# PIC32CM2532JH00100 register map
Vendor: Microchip Technology; Series: PIC32CMJH00; File version: 0
CPU: CM0+ r0p0, little endian, MPU, no FPU, VTOR, 2 interrupt priority bits, 32 interrupts
Registers are 32-bit, read-write, reset 0x0 unless marked. A register's access mark holds for its fields unless they carry their own. Offsets are from the block's base; [hi:lo] are bit positions; lines under a group give offsets from that group; {n}, {i} and the like mark numbered series; 'fields as' and 'values as' point back to an identical list.

## SERCOM0 — Serial Communication Interface
Base 0x42000400; register names take the prefix SERCOM_
Same registers: SERCOM1 0x42000800, SERCOM2 0x42000C00, SERCOM3 0x42001000, SERCOM4 0x42001400, SERCOM5 0x42001800, SERCOM6 0x43000000, SERCOM7 0x43000400
0x00 I2CM group — I2C Host Mode
  0x00 CTRLA — I2CM Control A
    [30] LOWTOUTEN — SCL Low Time-Out
    [29:28] INACTOUT — Inactive Time-Out
      0=DIS (Disabled); 1=55US (5-6 SCL cycle time-out (50-60 us)); 2=105US (10-11 SCL cycle time-out (100-110 us)); 3=205US (20-21 SCL cycle time-out (200-210 us))
    [27] SCLSM — SCL Clock Stretch Mode
    [25:24] SPEED — Transfer Speed
      0=SM_MODE (Standard-mode (Sm) and Fast-mode (Fm)); 1=FASTPLUS_MODE (Fast-mode Plus (Fm+))
    [23] SEXTTOEN — Client SCL Low Extend Time-Out
    [22] MEXTTOEN — Host SCL Low Extend Time-Out
    [21:20] SDAHOLD — SDA Hold Time
      0=DIS (SDA hold time is disabled); 1=75NS (SDA hold time is 50-100 ns); 2=450NS (SDA hold time is 300-600 ns); 3=600NS (SDA hold time is 400-800 ns)
    [16] PINOUT — Pin Usage
    [7] RUNSTDBY — Run in Standby
    [4:2] MODE — Operating Mode
      0=USART_EXT (USART with external clock); 1=USART_INT (USART with internal clock); 2=SPI_SLAVE (SPI Client mode); 3=SPI_MASTER (SPI Host mode); 4=I2C_SLAVE (I2C Client mode); 5=I2C_MASTER (I2C Host mode)
    [1] ENABLE
    [0] SWRST — Software Reset
  0x04 CTRLB — I2CM Control B
    [18] ACKACT — Acknowledge Action
    [17:16] CMD — Command
    [9] QCEN — Quick Command Enable
    [8] SMEN — Smart Mode Enable
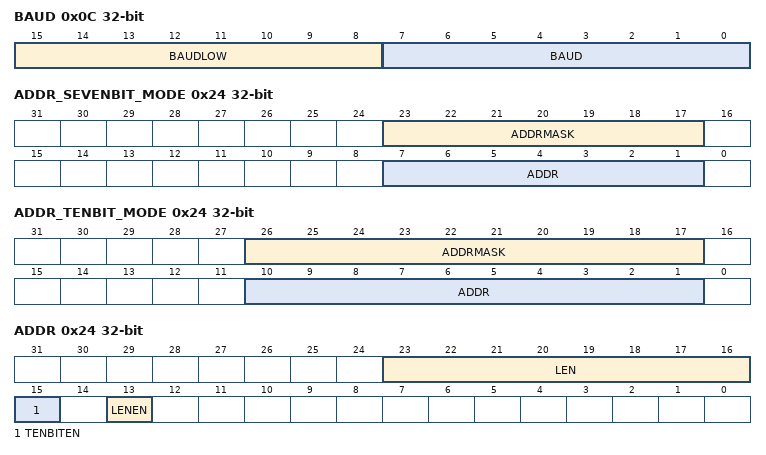
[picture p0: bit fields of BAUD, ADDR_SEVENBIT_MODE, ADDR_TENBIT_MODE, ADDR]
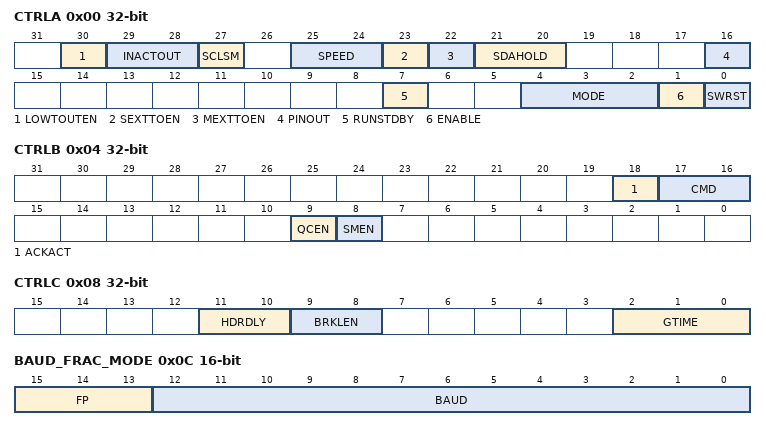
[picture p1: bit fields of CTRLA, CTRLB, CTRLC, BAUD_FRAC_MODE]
  0x0C BAUD — I2CM Baud Rate
    [15:8] BAUDLOW — Host Baud Rate Low
    [7:0] BAUD — Host Baud Rate
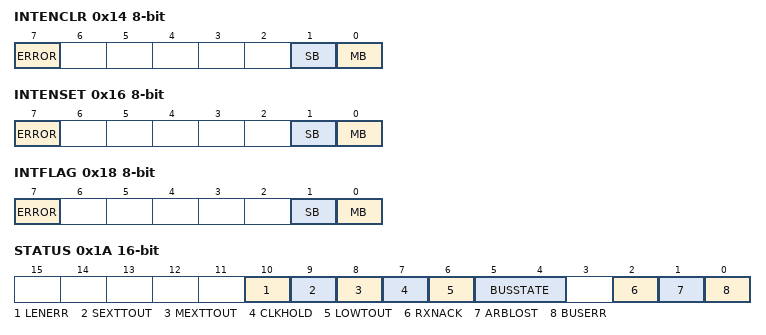
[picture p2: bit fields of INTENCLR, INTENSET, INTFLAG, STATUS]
  0x14 INTENCLR 8-bit write-1-clears — I2CM Interrupt Enable Clear
    [7] ERROR — Error Interrupt Enable
    [1] SB — Client on Bus Interrupt Enable
    [0] MB — Host on Bus Interrupt Enable
  0x16 INTENSET 8-bit write-1-sets — I2CM Interrupt Enable Set
    fields as I2CM.INTENCLR
  0x18 INTFLAG 8-bit write-1-clears — I2CM Interrupt Flag Status and Clear
    [7] ERROR
    [1] SB — Client on Bus
    [0] MB — Host on Bus
  0x1A STATUS 16-bit — I2CM Status
    [10] LENERR — Transaction Length Error
    [9] SEXTTOUT — Client SCL Low Extend Time-Out
    [8] MEXTTOUT — Host SCL Low Extend Time-Out
    [7] CLKHOLD — Clock Hold
    [6] LOWTOUT — SCL Low Time-Out
    [5:4] BUSSTATE
      0=UNKNOWN (The bus state is unknown to the I2C host, which will wait for a stop condition to be detected or for the bus to be forced into the IDLE state by software); 1=IDLE (The bus state is waiting for a transaction to be initialized); 2=OWNER (The I2C host is the current owner of the bus); 3=BUSY (Some other I2C host owns the bus)
    [2] RXNACK — Received Not Acknowledge
    [1] ARBLOST — Arbitration Lost
    [0] BUSERR — Bus Error
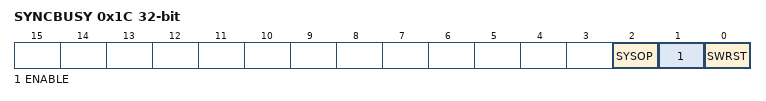
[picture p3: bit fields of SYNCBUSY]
  0x1C SYNCBUSY ro — I2CM Synchronization Busy
    [2] SYSOP — System Operation Synchronization Busy
    [1] ENABLE — SERCOM Enable Synchronization Busy
    [0] SWRST — Software Reset Synchronization Busy
  0x24 ADDR — I2CM Address
    [23:16] LEN — Transaction Length
    [15] TENBITEN — Ten Bit Addressing Enable
    [13] LENEN — Transfer Length Enable
  0x24 ADDR_SEVENBIT_MODE (alternate view of ADDR) — I2CM Address
    [6:0] ADDR — Address
  0x24 ADDR_TENBIT_MODE (alternate view of ADDR) — I2CM Address
    [9:0] ADDR — Address
  0x28 DATA 8-bit — I2CM Data
  0x30 DBGCTRL 8-bit — I2CM Debug Control
    [0] DBGSTOP — Debug Stop Mode
0x00 I2CS group (alternate view of I2CM) — I2C Client Mode
  0x00 CTRLA — I2CS Control A
    [30] LOWTOUTEN — SCL Low Time-Out
    [27] SCLSM — SCL Clock Stretch Mode
    [25:24] SPEED — Transfer Speed
      values as I2CM.CTRLA.SPEED
    [23] SEXTTOEN — Client SCL Low Extend Time-Out
    [21:20] SDAHOLD — SDA Hold Time
      0=DIS (Disabled); 1=75NS (50-100 ns hold time); 2=450NS (300-600 ns hold time); 3=600NS (400-800 ns hold time)
    [16] PINOUT — Pin Usage
    [7] RUNSTDBY — Run in Standby
    [4:2] MODE — Operating Mode
      values as I2CM.CTRLA.MODE
    [1] ENABLE
    [0] SWRST — Software Reset
  0x04 CTRLB — I2CS Control B
    [18] ACKACT — Acknowledge Action
    [17:16] CMD — Command
    [15:14] AMODE — Address Mode
      0=MASK (The client responds to the address written in ADDR.ADDR masked by the value in ADDR.ADDRMASK. See SERCOM - Serial Communication Interface for additional information.); 1=2ADDRS (The client responds to the two unique addresses in ADDR.ADDR and ADDR.ADDRMASK); 2=RANGE (The client responds to the range of addresses between and including ADDR.ADDR and ADDR.ADDRMASK. ADDR.ADDR is the upper limit.)
    [10] AACKEN — Automatic Acknowledge Enable
    [9] GCMD — PMBus Group Command
    [8] SMEN — Smart Mode Enable
  0x14 INTENCLR 8-bit write-1-clears — I2CS Interrupt Enable Clear
    [7] ERROR — Error Interrupt Enable
    [2] DRDY — Data Ready Interrupt Enable
    [1] AMATCH — Address Match Interrupt Enable
    [0] PREC — Stop Received Interrupt Enable
  0x16 INTENSET 8-bit write-1-sets — I2CS Interrupt Enable Set
    fields as I2CS.INTENCLR
  0x18 INTFLAG 8-bit write-1-clears — I2CS Interrupt Flag Status and Clear
    [7] ERROR
    [2] DRDY — Data Ready
    [1] AMATCH — Address Match
    [0] PREC — Stop Received
  0x1A STATUS 16-bit — I2CS Status
    [9] SEXTTOUT — Client SCL Low Extend Time-Out
    [7] CLKHOLD — Clock Hold
    [6] LOWTOUT — SCL Low Time-out
    [4] SR — Repeated Start
    [3] DIR — Read / Write Direction
    [2] RXNACK — Received Not Acknowledge
    [1] COLL — Transmit Collision
    [0] BUSERR — Bus Error
  0x1C SYNCBUSY ro — I2CS Synchronization Busy
    [1] ENABLE — SERCOM Enable Synchronization Busy
    [0] SWRST — Software Reset Synchronization Busy
  0x24 ADDR — I2CS Address
    [15] TENBITEN — Ten Bit Addressing Enable
    [0] GENCEN — General Call Address Enable
  0x24 ADDR_SEVENBIT_MODE (alternate view of ADDR) — I2CS Address
    [23:17] ADDRMASK — Address Mask
    [7:1] ADDR — Address
  0x24 ADDR_TENBIT_MODE (alternate view of ADDR) — I2CS Address
    [26:17] ADDRMASK — Address Mask
    [10:1] ADDR — Address
  0x28 DATA 8-bit — I2CS Data
0x00 SPI group (alternate view of I2CM) — SPI Mode
  0x00 CTRLA — SPI Control A
    [30] DORD — Data Order
      0=MSB (MSb is transferred first); 1=LSB (LSb is transferred first)
    [29] CPOL — Clock Polarity
      0=IDLE_LOW (SCK is low when IDLE. The leading edge of a clock cycle is a rising edge, while the trailing edge is a falling edge.); 1=IDLE_HIGH (SCK is high when IDLE. The leading edge of a clock cycle is a falling edge, while the trailing edge is a rising edge.)
    [28] CPHA — Clock Phase
      0=LEADING_EDGE (The data is sampled on a leading SCK edge and changed on a trailing SCK edge); 1=TRAILING_EDGE (The data is sampled on a trailing SCK edge and changed on a leading SCK edge)
    [27:24] FORM — Frame Format
      0=SPI_FRAME; 2=SPI_FRAME_WITH_ADDR (SPI Frame with Address)
    [21:20] DIPO — Data In Pinout
      {v}=MUX{v} (SERCOM PAD[{v}] is used as data input) (v=0..3)
    [17:16] DOPO — Data Out Pinout
      0=MUX0 (PAD[0]=DO, PAD[1]=SCK, PAD[2]=SS); 1=MUX1 (PAD[2]=DO, PAD[3]=SCK, PAD[1]=SS); 2=MUX2 (PAD[3]=DO, PAD[1]=SCK, PAD[2]=SS); 3=MUX3 (PAD[0]=DO, PAD[3]=SCK, PAD[1]=SS)
    [8] IBON — Immediate Buffer Overflow Notification
    [7] RUNSTDBY — Run In Standby
    [4:2] MODE — Operating Mode
      values as I2CM.CTRLA.MODE
    [1] ENABLE
    [0] SWRST — Software Reset
  0x04 CTRLB — SPI Control B
    [17] RXEN — Receiver Enable
    [15:14] AMODE — Address Mode
      0=MASK (ADDRMASK is used as a mask to the ADDR register); 1=2ADDRS (The client responds to the two unique addresses in ADDR and ADDRMASK); 2=RANGE (The client responds to the range of addresses between and including ADDR and ADDRMASK with ADDR as the upper limit)
    [13] MSSEN — Host SPI Select Enable
    [9] SSDE — SPI Select Low Detect Enable
    [6] PLOADEN — Client Data Preload Enable
    [2:0] CHSIZE — Character Size
      0=8_BIT (Eight bits); 1=9_BIT (Nine bits)
  0x0C BAUD 8-bit — SPI Baud Rate
  0x14 INTENCLR 8-bit write-1-clears — SPI Interrupt Enable Clear
    [7] ERROR — Error Interrupt Enable
    [3] SSL — SPI Select Low Interrupt Enable
    [2] RXC — Receive Complete Interrupt Enable
    [1] TXC — Transmit Complete Interrupt Enable
    [0] DRE — Data Register Empty Interrupt Enable
  0x16 INTENSET 8-bit write-1-sets — SPI Interrupt Enable Set
    fields as SPI.INTENCLR
  0x18 INTFLAG 8-bit write-1-clears — SPI Interrupt Flag Status and Clear
    [7] ERROR
    [3] SSL — SPI Select Low
    [2] RXC — Receive Complete
    [1] TXC — Transmit Complete
    [0] DRE — Data Register Empty
  0x1A STATUS 16-bit — SPI Status
    [2] BUFOVF — Buffer Overflow
  0x1C SYNCBUSY ro — SPI Synchronization Busy
    [2] CTRLB — CTRLB Synchronization Busy
    [1] ENABLE — SERCOM Enable Synchronization Busy
    [0] SWRST — Software Reset Synchronization Busy
  0x24 ADDR — SPI Address
    [23:16] ADDRMASK — Address Mask
    [7:0] ADDR — Address
  0x28 DATA 16-bit — SPI Data
    [8:0] DATA
  0x30 DBGCTRL 8-bit — SPI Debug Control
    [0] DBGSTOP — Debug Stop Mode
0x00 USART group (alternate view of I2CM) — USART Mode
  0x00 CTRLA — USART Control A
    [30] DORD — Data Order
      values as SPI.CTRLA.DORD
    [29] CPOL — Clock Polarity
      0=IDLE_LOW (TxD Change: Rising XCK edge, RxD Sample: Falling XCK edge); 1=IDLE_HIGH (TxD Change: Falling XCK edge, RxD Sample: Rising XCK edge)
    [28] CMODE — Communication Mode
      0=ASYNC (Asynchronous communication); 1=SYNC (Synchronous communication)
    [27:24] FORM — Frame Format
      0=USART_FRAME_NO_PARITY; 1=USART_FRAME_WITH_PARITY; 2=USART_FRAME_LINBRKGEN (LIN Host - Break and sync generation. See LIN Command (CTRLB.LINCMD).); 4=USART_FRAME_AUTO_BAUD_NO_PARITY (Auto-baud (LIN Client) - break detection and auto-baud); 5=USART_FRAME_AUTO_BAUD_WITH_PARITY (Auto-baud - break detection and auto-baud with parity)
    [23:22] SAMPA — Sample Adjustment
      0=ADJ0 (16x Over-sampling = 7-8-9; 8x Over-sampling = 3-4-5); 1=ADJ1 (16x Over-sampling = 9-10-11; 8x Over-sampling = 4-5-6); 2=ADJ2 (16x Over-sampling = 11-12-13; 8x Over-sampling = 5-6-7); 3=ADJ3 (16x Over-sampling = 13-14-15; 8x Over-sampling = 6-7-8)
    [21:20] RXPO — Receive Data Pinout
      {v}=MUX{v} (SERCOM PAD[{v}] is used for data reception) (v=0..3)
    [17:16] TXPO — Transmit Data Pinout
      0=MUX0 (PAD[0]=TxD, PAD[1]=XCK); 1=MUX1 (PAD[2]=TxD, PAD[3]=XCK); 2=MUX2 (PAD[0]=TxD, PAD[2]=RTS/TE, PAD[3]=CTS); 3=MUX3 (PAD[0]=TxD, PAD[1]=XCK, PAD[2]=RTS/TE)
    [15:13] SAMPR — Sample Rate
      0=16X_ARITHMETIC (16x over-sampling using arithmetic baud rate generation); 1=16X_FRACTIONAL (16x over-sampling using fractional baud rate generation); 2=8X_ARITHMETIC (8x over-sampling using arithmetic baud rate generation); 3=8X_FRACTIONAL (8x over-sampling using fractional baud rate generation); 4=3X_ARITHMETIC (3x over-sampling using arithmetic baud rate generation)
    [8] IBON — Immediate Buffer Overflow Notification
    [7] RUNSTDBY — Run In Standby
    [4:2] MODE — Operating Mode
      values as I2CM.CTRLA.MODE
    [1] ENABLE
    [0] SWRST — Software Reset
  0x04 CTRLB — USART Control B
    [25:24] LINCMD — LIN Command
      0=NONE (Normal USART transmission); 1=SOFTWARE_CONTROL_TRANSMIT_CMD (A break field is transmitted when DATA is written); 2=AUTO_TRANSMIT_CMD (The break, sync, and identifier fields are automatically transmitted when the DATA is written with the identifier)
    [17] RXEN — Receiver Enable
    [16] TXEN — Transmitter Enable
    [13] PMODE — Parity Mode
      0=EVEN (Even parity); 1=ODD (Odd parity)
    [10] ENC — Encoding Format
      1=IRDA (Data is IrDA encoded)
    [9] SFDE — Start of Frame Detection Enable
    [8] COLDEN — Collision Detection Enable
    [6] SBMODE — Stop Bit Mode
      0=1_BIT (One stop bit); 1=2_BIT (Two stop bits)
    [2:0] CHSIZE — Character Size
      0=8_BIT (8-bits character); 1=9_BIT (9-bits character); 5=5_BIT (5-bits character); 6=6_BIT (6-bits character); 7=7_BIT (7-bits character)
  0x08 CTRLC — USART Control C
    [11:10] HDRDLY — LIN Host Header Delay
      0=1_BIT_TIME (Delay between break and sync transmission is one bit time. Delay between sync and ID transmission is one bit time.); 1=4_BIT_TIME (Delay between break and sync transmission is four bit times. Delay between sync and ID transmission is four bit times.); 2=8_BIT_TIME (Delay between break and sync transmission is eight bit times. Delay between sync and ID transmission is four bit times.); 3=14_BIT_TIME (Delay between break and sync transmission is 14 bit times. Delay between sync and ID transmission is four bit times.)
    [9:8] BRKLEN — LIN Host Break Length
      0=13_BIT_TIME (The break field transmission is 13 bit times); 1=17_BIT_TIME (The break field transmission is 17 bit times); 2=21_BIT_TIME (The break field transmission is 21 bit times); 3=26_BIT_TIME (The break field transmission is 26 bit times)
    [2:0] GTIME — Guard Time
  0x0C BAUD_ARITH_MODE 16-bit — USART Baud
    [15:0] BAUD — Baud Value
  0x0C BAUD_FRAC_MODE 16-bit (alternate view of BAUD_ARITH_MODE) — USART Baud
    [15:13] FP — Fractional Part
    [12:0] BAUD — Baud Value
  0x0E RXPL 8-bit — USART Receive Pulse Length
    [7:0] RXPL — Receive Pulse Length
  0x14 INTENCLR 8-bit write-1-clears — USART Interrupt Enable Clear
    [7] ERROR — Error Interrupt Enable
    [5] RXBRK — Receive Break Interrupt Enable
    [4] CTSIC — Clear to Send Input Change Interrupt Enable
    [3] RXS — Receive Start Interrupt Enable
    [2] RXC — Receive Complete Interrupt Enable
    [1] TXC — Transmit Complete Interrupt Enable
    [0] DRE — Data Register Empty Interrupt Enable
  0x16 INTENSET 8-bit write-1-sets — USART Interrupt Enable Set
    fields as USART.INTENCLR
  0x18 INTFLAG 8-bit write-1-clears — USART Interrupt Flag Status and Clear
    [7] ERROR
    [5] RXBRK — Receive Break
    [4] CTSIC — Clear to Send Input Change
    [3] RXS — Receive Start
    [2] RXC — Receive Complete
    [1] TXC — Transmit Complete
    [0] DRE — Data Register Empty
  0x1A STATUS 16-bit — USART Status
    [6] TXE — Transmitter Empty
    [5] COLL — Collision Detected
    [4] ISF — Inconsistent Sync Field
    [3] CTS — Clear to Send
    [2] BUFOVF — Buffer Overflow
    [1] FERR — Frame Error
    [0] PERR — Parity Error
  0x1C SYNCBUSY ro — USART Synchronization Busy
    fields as SPI.SYNCBUSY
  0x28 DATA 16-bit — USART Data
    [8:0] DATA
  0x30 DBGCTRL 8-bit — USART Debug Control
    [0] DBGSTOP — Debug Stop Mode
